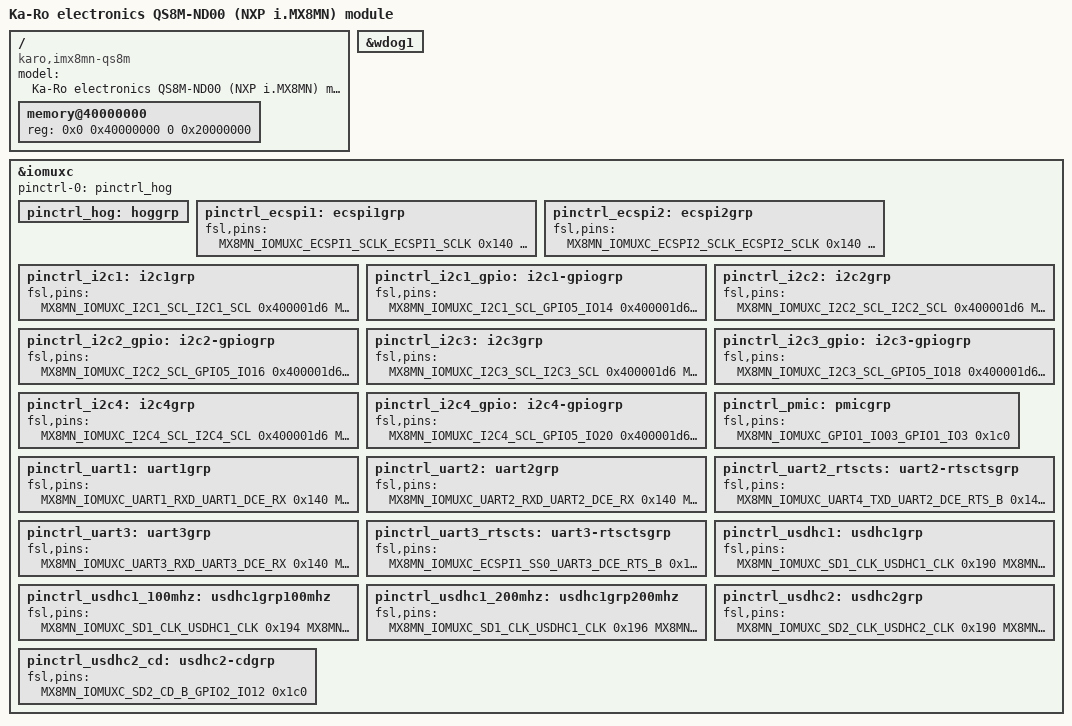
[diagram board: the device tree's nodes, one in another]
// SPDX-License-Identifier: (GPL-2.0 OR MIT)
/*
 * Copyright (C) 2020 Lothar Waßmann <LW@KARO-electronics.de>
 *
 */

/dts-v1/;

#include "imx8mn.dtsi"
#include "imx8m-qs8m.dtsi"

/ {
	model = "Ka-Ro electronics QS8M-ND00 (NXP i.MX8MN) module";
	compatible = "karo,imx8mn-qs8m", "fsl,imx8mn";

	memory@40000000 {
		device_type = "memory";
		reg = <0x0 0x40000000 0 0x20000000>;
	};
};

&wdog1 {
	pinctrl-names = "default";
	status = "okay";
};

&iomuxc {
	pinctrl-names = "default";
	pinctrl-0 = <&pinctrl_hog>;

	pinctrl_hog: hoggrp {
	};

	pinctrl_ecspi1: ecspi1grp {
		fsl,pins = <
			MX8MN_IOMUXC_ECSPI1_SCLK_ECSPI1_SCLK		0x140
			MX8MN_IOMUXC_ECSPI1_MOSI_ECSPI1_MOSI		0x140
			MX8MN_IOMUXC_ECSPI1_MISO_ECSPI1_MISO		0x140
			MX8MN_IOMUXC_ECSPI1_SS0_GPIO5_IO9		0x140
		>;
	};

	pinctrl_ecspi2: ecspi2grp {
		fsl,pins = <
			MX8MN_IOMUXC_ECSPI2_SCLK_ECSPI2_SCLK		0x140
			MX8MN_IOMUXC_ECSPI2_MOSI_ECSPI2_MOSI		0x140
			MX8MN_IOMUXC_ECSPI2_MISO_ECSPI2_MISO		0x140
			MX8MN_IOMUXC_ECSPI2_SS0_GPIO5_IO13		0x140
		>;
	};

	pinctrl_i2c1: i2c1grp {
		fsl,pins = <
			MX8MN_IOMUXC_I2C1_SCL_I2C1_SCL			0x400001d6
			MX8MN_IOMUXC_I2C1_SDA_I2C1_SDA			0x400001d6
		>;
	};

	pinctrl_i2c1_gpio: i2c1-gpiogrp {
		fsl,pins = <
			MX8MN_IOMUXC_I2C1_SCL_GPIO5_IO14		0x400001d6
			MX8MN_IOMUXC_I2C1_SDA_GPIO5_IO15		0x400001d6
		>;
	};

	pinctrl_i2c2: i2c2grp {
		fsl,pins = <
			MX8MN_IOMUXC_I2C2_SCL_I2C2_SCL			0x400001d6
			MX8MN_IOMUXC_I2C2_SDA_I2C2_SDA			0x400001d6
		>;
	};

	pinctrl_i2c2_gpio: i2c2-gpiogrp {
		fsl,pins = <
			MX8MN_IOMUXC_I2C2_SCL_GPIO5_IO16		0x400001d6
			MX8MN_IOMUXC_I2C2_SDA_GPIO5_IO17		0x400001d6
		>;
	};

	pinctrl_i2c3: i2c3grp {
		fsl,pins = <
			MX8MN_IOMUXC_I2C3_SCL_I2C3_SCL			0x400001d6
			MX8MN_IOMUXC_I2C3_SDA_I2C3_SDA			0x400001d6
		>;
	};

	pinctrl_i2c3_gpio: i2c3-gpiogrp {
		fsl,pins = <
			MX8MN_IOMUXC_I2C3_SCL_GPIO5_IO18		0x400001d6
			MX8MN_IOMUXC_I2C3_SDA_GPIO5_IO19		0x400001d6
		>;
	};

	pinctrl_i2c4: i2c4grp {
		fsl,pins = <
			MX8MN_IOMUXC_I2C4_SCL_I2C4_SCL			0x400001d6
			MX8MN_IOMUXC_I2C4_SDA_I2C4_SDA			0x400001d6
		>;
	};

	pinctrl_i2c4_gpio: i2c4-gpiogrp {
		fsl,pins = <
			MX8MN_IOMUXC_I2C4_SCL_GPIO5_IO20		0x400001d6
			MX8MN_IOMUXC_I2C4_SDA_GPIO5_IO21		0x400001d6
		>;
	};

	pinctrl_pmic: pmicgrp {
		fsl,pins = <
			MX8MN_IOMUXC_GPIO1_IO03_GPIO1_IO3		0x1c0
		>;
	};

	pinctrl_uart1: uart1grp {
		fsl,pins = <
			MX8MN_IOMUXC_UART1_RXD_UART1_DCE_RX		0x140
			MX8MN_IOMUXC_UART1_TXD_UART1_DCE_TX		0x140
		>;
	};

	pinctrl_uart2: uart2grp {
		fsl,pins = <
			MX8MN_IOMUXC_UART2_RXD_UART2_DCE_RX		0x140
			MX8MN_IOMUXC_UART2_TXD_UART2_DCE_TX		0x140
		>;
	};

	pinctrl_uart2_rtscts: uart2-rtsctsgrp {
		fsl,pins = <
			MX8MN_IOMUXC_UART4_TXD_UART2_DCE_RTS_B		0x140
			MX8MN_IOMUXC_UART4_RXD_UART2_DCE_CTS_B		0x140
		>;
	};

	pinctrl_uart3: uart3grp {
		fsl,pins = <
			MX8MN_IOMUXC_UART3_RXD_UART3_DCE_RX		0x140
			MX8MN_IOMUXC_UART3_TXD_UART3_DCE_TX		0x140
		>;
	};

	pinctrl_uart3_rtscts: uart3-rtsctsgrp {
		fsl,pins = <
			MX8MN_IOMUXC_ECSPI1_SS0_UART3_DCE_RTS_B		0x140
			MX8MN_IOMUXC_ECSPI1_MISO_UART3_DCE_CTS_B	0x140
		>;
	};

	pinctrl_usdhc1: usdhc1grp {
		fsl,pins = <
			MX8MN_IOMUXC_SD1_CLK_USDHC1_CLK			0x190
			MX8MN_IOMUXC_SD1_CMD_USDHC1_CMD			0x1d0
			MX8MN_IOMUXC_SD1_DATA0_USDHC1_DATA0		0x1d0
			MX8MN_IOMUXC_SD1_DATA1_USDHC1_DATA1		0x1d0
			MX8MN_IOMUXC_SD1_DATA2_USDHC1_DATA2		0x1d0
			MX8MN_IOMUXC_SD1_DATA3_USDHC1_DATA3		0x1d0
			MX8MN_IOMUXC_SD1_DATA4_USDHC1_DATA4		0x1d0
			MX8MN_IOMUXC_SD1_DATA5_USDHC1_DATA5		0x1d0
			MX8MN_IOMUXC_SD1_DATA6_USDHC1_DATA6		0x1d0
			MX8MN_IOMUXC_SD1_DATA7_USDHC1_DATA7		0x1d0
			MX8MN_IOMUXC_SD1_STROBE_USDHC1_STROBE		0x156
			MX8MN_IOMUXC_SD1_RESET_B_USDHC1_RESET_B		0x156
		>;
	};

	pinctrl_usdhc1_100mhz: usdhc1grp100mhz {
		fsl,pins = <
			MX8MN_IOMUXC_SD1_CLK_USDHC1_CLK			0x194
			MX8MN_IOMUXC_SD1_CMD_USDHC1_CMD			0x1d4
			MX8MN_IOMUXC_SD1_DATA0_USDHC1_DATA0		0x1d4
			MX8MN_IOMUXC_SD1_DATA1_USDHC1_DATA1		0x1d4
			MX8MN_IOMUXC_SD1_DATA2_USDHC1_DATA2		0x1d4
			MX8MN_IOMUXC_SD1_DATA3_USDHC1_DATA3		0x1d4
			MX8MN_IOMUXC_SD1_DATA4_USDHC1_DATA4		0x1d4
			MX8MN_IOMUXC_SD1_DATA5_USDHC1_DATA5		0x1d4
			MX8MN_IOMUXC_SD1_DATA6_USDHC1_DATA6		0x1d4
			MX8MN_IOMUXC_SD1_DATA7_USDHC1_DATA7		0x1d4
			MX8MN_IOMUXC_SD1_STROBE_USDHC1_STROBE		0x156
			MX8MN_IOMUXC_SD1_RESET_B_USDHC1_RESET_B		0x156
		>;
	};

	pinctrl_usdhc1_200mhz: usdhc1grp200mhz {
		fsl,pins = <
			MX8MN_IOMUXC_SD1_CLK_USDHC1_CLK			0x196
			MX8MN_IOMUXC_SD1_CMD_USDHC1_CMD			0x1d6
			MX8MN_IOMUXC_SD1_DATA0_USDHC1_DATA0		0x1d6
			MX8MN_IOMUXC_SD1_DATA1_USDHC1_DATA1		0x1d6
			MX8MN_IOMUXC_SD1_DATA2_USDHC1_DATA2		0x1d6
			MX8MN_IOMUXC_SD1_DATA3_USDHC1_DATA3		0x1d6
			MX8MN_IOMUXC_SD1_DATA4_USDHC1_DATA4		0x1d6
			MX8MN_IOMUXC_SD1_DATA5_USDHC1_DATA5		0x1d6
			MX8MN_IOMUXC_SD1_DATA6_USDHC1_DATA6		0x1d6
			MX8MN_IOMUXC_SD1_DATA7_USDHC1_DATA7		0x1d6
			MX8MN_IOMUXC_SD1_STROBE_USDHC1_STROBE		0x156
			MX8MN_IOMUXC_SD1_RESET_B_USDHC1_RESET_B		0x156
		>;
	};

	pinctrl_usdhc2: usdhc2grp {
		fsl,pins = <
			MX8MN_IOMUXC_SD2_CLK_USDHC2_CLK			0x190
			MX8MN_IOMUXC_SD2_CMD_USDHC2_CMD			0x1d0
			MX8MN_IOMUXC_SD2_DATA0_USDHC2_DATA0		0x1d0
			MX8MN_IOMUXC_SD2_DATA1_USDHC2_DATA1		0x1d0
			MX8MN_IOMUXC_SD2_DATA2_USDHC2_DATA2		0x1d0
			MX8MN_IOMUXC_SD2_DATA3_USDHC2_DATA3		0x1d0
		>;
	};

	pinctrl_usdhc2_cd: usdhc2-cdgrp {
		fsl,pins = <
			MX8MN_IOMUXC_SD2_CD_B_GPIO2_IO12		0x1c0
		>;
	};
};
